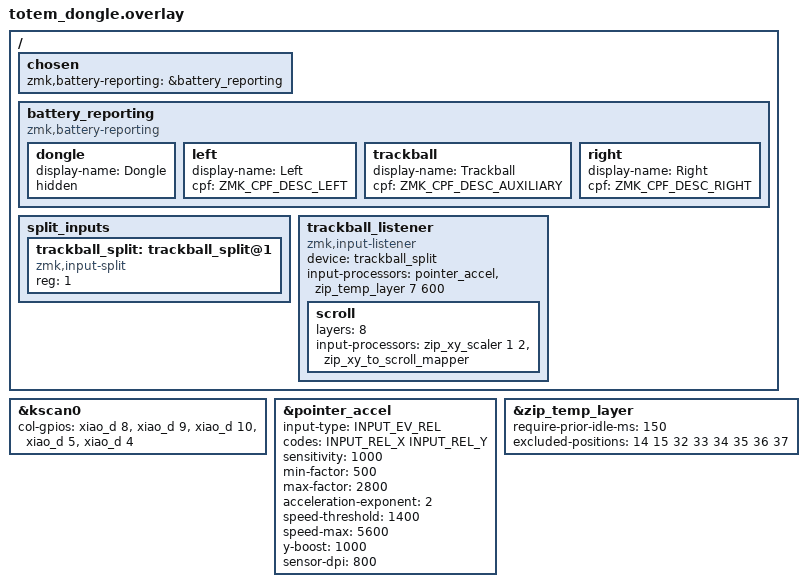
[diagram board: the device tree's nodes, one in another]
/*
 * Copyright (c) 2022 The ZMK Contributors
 *
 * SPDX-License-Identifier: MIT
 */

#include "totem.dtsi"
#include <input/processors/scaler.dtsi>
#include <input/processors/temp_layer.dtsi>
#include <input/processors.dtsi>
#include <behaviors/input_gestures_accel.dtsi>
#include <zephyr/dt-bindings/input/input-event-codes.h>
#include <dt-bindings/zmk/battery_reporting.h>

 &kscan0 {
     col-gpios
         = <&xiao_d 8 GPIO_ACTIVE_HIGH>
         , <&xiao_d 9 GPIO_ACTIVE_HIGH>
         , <&xiao_d 10 GPIO_ACTIVE_HIGH>
         , <&xiao_d 5 GPIO_ACTIVE_HIGH>
         , <&xiao_d 4 GPIO_ACTIVE_HIGH>
         ;
 };

/* Pointer acceleration - velocity based, tuned for a 1600 CPI PMW3610 driving a
 * single 3840x2160 27" display (163 PPI) on X11/i3, where the pointer space is
 * unscaled: 1 count = 1 physical pixel.
 *
 * Resulting gearing, in pixels per inch of ball travel:
 *   slow (min-factor)  0.5 x 1600 =  800 px/in  - fine positioning
 *   flick (max-factor) 2.8 x 1600 = 4480 px/in  - 3840 px wide screen crossed in
 *                                                0.86", the 4406 px diagonal in 0.98"
 *                                                i.e. one sweep of the 34mm ball
 *
 * Must be declared before the input-listener that references it.
 */
&pointer_accel {
    input-type = <INPUT_EV_REL>;
    codes = <INPUT_REL_X INPUT_REL_Y>;

    sensitivity = <1000>;         // 1.0x base
    min-factor = <500>;           // 0.5x below the threshold, for fine positioning
    max-factor = <2800>;          // 2.8x once at speed-max (ceiling is 5000)
    acceleration-exponent = <2>;  // mild exponential ramp between the two
    speed-threshold = <1400>;     // counts/sec; ~0.9 in/s of ball travel at 1600 CPI
    speed-max = <5600>;           // ~3.5 in/s - both doubled with the CPI change,
                                  // since counts/sec scale with sensor resolution
    y-boost = <1000>;             // 1.0x = same as X

    /* Deliberately NOT 1600. The driver normalizes as
     *   effective = sensitivity * 800 / sensor-dpi
     * (STANDARD_DPI_REFERENCE = 800, input_processor_accel_calc_common.c:69-87),
     * so declaring the real 1600 would halve sensitivity and cancel the CPI
     * increase exactly. Treat this as the normalization reference, not hardware
     * truth. The honest alternative is sensor-dpi = <1600> with
     * sensitivity = <2000>, which computes to the same 1.0x but leaves no
     * headroom, as 2000 is the sensitivity ceiling.
     */
    sensor-dpi = <800>;
};

/* Battery reporting parts, one child per keyboard part, in order: central first,
 * then peripherals by split index. The count must equal 1 + PERIPHERALS (=4) or
 * the build asserts.
 *
 * The dongle child is `hidden` on purpose: the lowest-charge aggregation takes
 * the central's level unconditionally, while peripheral zeros are skipped
 * (battery_reporting.c:251-266). This dongle runs on USB with no cell attached,
 * so its phantom ADC reading would otherwise pin the reported minimum.
 *
 * Peripheral slots are assigned in split connection order, so the left/right/
 * trackball names are best-effort - swap them if the labels come out crossed.
 */
/ {
    chosen {
        zmk,battery-reporting = &battery_reporting;
    };

    battery_reporting: battery_reporting {
        compatible = "zmk,battery-reporting";

        dongle {
            display-name = "Dongle";
            hidden;
        };

        left {
            display-name = "Left";
            cpf = <ZMK_CPF_DESC_LEFT>;
        };

        trackball {
            display-name = "Trackball";
            cpf = <ZMK_CPF_DESC_AUXILIARY>;
        };

        right {
            display-name = "Right";
            cpf = <ZMK_CPF_DESC_RIGHT>;
        };
    };
};

/* Auto mouse layer guards.
 *
 * require-prior-idle-ms: ball movement within this long after a keystroke will
 * not activate the layer, so brushing the ball mid-word no longer hijacks the
 * keys. Raise toward 250 if it still triggers while typing.
 *
 * excluded-positions: positions listed here KEEP the layer alive when pressed;
 * every other key drops it instantly. Listed are the six thumb clicks (32-37)
 * and the two &mo 8 scroll keys (14, 15) - i.e. exactly the bindings that exist
 * on the button layer. So typing dismisses the layer immediately, which is what
 * lets the 1000ms timeout come down to 600.
 */
&zip_temp_layer {
    require-prior-idle-ms = <150>;
    excluded-positions = <14 15 32 33 34 35 36 37>;
};

 / {
    split_inputs {
        #address-cells = <1>;
        #size-cells = <0>;

        trackball_split: trackball_split@1 {
            compatible = "zmk,input-split";
            reg = <1>;  // Must match the peripheral's reg value
        };
    };

    /* Trackball listener - same layer-aware processing */
    trackball_listener {
        compatible = "zmk,input-listener";
        device = <&trackball_split>;
        // Acceleration + auto mouse layer. The old <&zip_xy_scaler 1 1> was a
        // 1:1 no-op and is now redundant.
        input-processors = <&pointer_accel>, <&zip_temp_layer 7 600>;
        
        /* Layer 8: Scroll mode - reduced sensitivity.
         * The divisor works on raw sensor counts. It went 16 -> 32 with the
         * 800 -> 1600 CPI change, then 32 -> 2 when smooth scrolling was enabled:
         * with the resolution multiplier at 16 each emitted unit is 1/16 of a
         * detent, so the divisor drops by the same factor to hold the speed while
         * giving 16x finer steps.
         */
        scroll {
            layers = <8>;
            input-processors = <&zip_xy_scaler 1 2>, <&zip_xy_to_scroll_mapper>;
        };
    };
};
